VERSION ""

NS_ :

BS_:

BU_:

BO_ 227 TBI_Temp: 1 Vector__XXX
 SG_ TBI_Temp : 0|1@1- (1,0) [0|0] "" Vector__XXX

BO_ 211 TBI_MAP: 1 Vector__XXX
 SG_ TBI_MAP : 0|1@1- (1,0) [0|0] "" Vector__XXX

BO_ 195 TBI: 1 Vector__XXX
 SG_ TBI : 0|1@1- (1,0) [0|0] "" Vector__XXX

BO_ 179 Strain_Gauge: 1 Vector__XXX
 SG_ Strain_Gauge : 0|1@1- (1,0) [0|0] "" Vector__XXX

BO_ 163 TPMS: 1 Vector__XXX
 SG_ TPMS : 0|1@1- (1,0) [0|0] "" Vector__XXX

BO_ 242 Rear_Brake_Fluid_Pressure: 1 Vector__XXX
 SG_ Rear_Brake_Fluid_Pressure : 0|8@1+ (0.0392,0) [0|9.996] "Bar" Vector__XXX

BO_ 226 Front_Brake_Fluid_Pressure: 1 Vector__XXX
 SG_ Front_Brake_Fluid_Pressure : 0|8@1+ (0.0392,0) [0|9.996] "Bar" Vector__XXX

BO_ 210 Accel_Pedal_Pos: 1 Vector__XXX
 SG_ Accel_Pedal_Pos : 0|1@1- (1,0) [0|0] "" Vector__XXX

BO_ 194 Brake_Pedal_Pos: 1 Vector__XXX
 SG_ Brake_Pedal_Pos : 0|1@1- (1,0) [0|0] "" Vector__XXX

BO_ 178 Front_Brake_Disk_Temp: 4 Vector__XXX
 SG_ R_Front_Brake_Disk_Temp : 16|10@1- (0.12219,22.56128) [-40|85.00037] "degC" Vector__XXX
 SG_ L_Front_Brake_Disk_Temp : 0|10@1- (0.12219,22.56128) [-40|85.00037] "degC" Vector__XXX

BO_ 162 Rear_Brake_Disk_Temp: 4 Vector__XXX
 SG_ R_Rear_Brake_Disk_Temp : 16|10@1- (0.12219,22.56128) [-40|85.00037] "degC" Vector__XXX
 SG_ L_Rear_Brake_Disk_Temp : 0|10@1- (0.12219,22.56128) [-40|85.00037] "degC" Vector__XXX

BO_ 241 Balance_Bar: 1 Vector__XXX
 SG_ Balance_Bar : 0|1@1- (1,0) [0|0] "" Vector__XXX

BO_ 225 Fuel_Pressure: 1 Vector__XXX
 SG_ Fuel_Pressure : 0|8@1+ (0.0392,0) [0|9.996] "Bar" Vector__XXX

BO_ 209 Battery_Current: 1 Vector__XXX
 SG_ Battery_Current : 0|1@1- (1,0) [0|0] "A" Vector__XXX

BO_ 193 Battery_Voltage: 1 Vector__XXX
 SG_ Battery_Voltage : 0|1@1- (1,0) [0|0] "V" Vector__XXX

BO_ 514 Gear_Pos: 1 Vector__XXX
 SG_ Gear_Pos : 0|8@1+ (1,0) [0|6] "Gear" Vector__XXX

BO_ 177 GPS: 1 Vector__XXX
 SG_ GPS : 0|1@1- (1,0) [0|0] "" Vector__XXX

BO_ 769 Speed: 1 Vector__XXX
 SG_ Speed : 0|8@1+ (1,0) [0|255] "km/h" Vector__XXX

BO_ 257 Lambda_Sensor: 1 Vector__XXX
 SG_ Lambda_Sensor : 0|8@1+ (0.01,0) [0|2.55] "" Vector__XXX

BO_ 513 Air_Temp: 1 Vector__XXX
 SG_ Air_Temp : 0|8@1+ (1,0) [0|255] "degC" Vector__XXX

BO_ 258 MAP: 2 Vector__XXX
 SG_ MAP : 0|10@1+ (250,0) [0|255750] "Pa" Vector__XXX

BO_ 2 RPM: 2 Vector__XXX
 SG_ RPM_Sensor : 0|16@1+ (1,0) [0|13000] "RPM" Vector__XXX

BO_ 259 TPS: 1 Vector__XXX
 SG_ TPS : 0|8@1+ (1,0) [0|255] "%" Vector__XXX

BO_ 518 Water_Temp: 1 Vector__XXX
 SG_ Water_Temp : 0|8@1+ (1,0) [0|255] "degC" Vector__XXX

BO_ 1 Oil_Pressure: 1 Vector__XXX
 SG_ Oil_Pressure : 0|8@1+ (0.0392,0) [0|9.996] "Bar" Vector__XXX

BO_ 515 Oil_Temp: 1 Vector__XXX
 SG_ Oil_Temp : 0|8@1+ (1,0) [0|255] "degC" Vector__XXX

BO_ 161 Intercooler_Output_Pressure: 1 Vector__XXX
 SG_ Intercooler_Output_Pressure : 0|1@1- (1,0) [0|0] "" Vector__XXX

BO_ 15 Turbo_Intercooler_Pressure: 1 Vector__XXX
 SG_ Turbo_Intercooler_Pressure : 0|1@1- (1,0) [0|0] "" Vector__XXX

BO_ 14 Rest_Turbo_Pressure: 1 Vector__XXX
 SG_ Rest_Turbo_Pressure : 0|1@1- (1,0) [0|0] "" Vector__XXX

BO_ 13 Intercooler_Output_Temp: 1 Vector__XXX
 SG_ Intercooler_Output_Temp : 0|1@1- (1,0) [0|0] "degC" Vector__XXX

BO_ 12 Turbo_Intercooler_Temp: 1 Vector__XXX
 SG_ Turbo_Intercooler_Temp : 0|1@1- (1,0) [0|0] "degC" Vector__XXX

BO_ 11 Rest_Turbo_Temp: 1 Vector__XXX
 SG_ Rest_Turbo_Temp : 0|1@1- (1,0) [0|0] "degC" Vector__XXX

BO_ 1029 Rear_Susp_Pos: 4 Vector__XXX
 SG_ R_Rear_Susp_Pos : 16|10@1+ (0.088,0) [0|90.024] "deg" Vector__XXX
 SG_ L_Rear_Susp_Pos : 0|10@1+ (0.088,0) [0|90.024] "deg" Vector__XXX

BO_ 1028 Front_Susp_Pos: 4 Vector__XXX
 SG_ R_Front_Susp_Pos : 16|10@1+ (0.088,0) [0|90.024] "deg" Vector__XXX
 SG_ L_Front_Susp_Pos : 0|10@1+ (0.088,0) [0|90.024] "deg" Vector__XXX

BO_ 10 Steering_Wheel_Pos: 1 Vector__XXX
 SG_ Steering_Wheel_Pos : 0|1@1- (1,0) [0|0] "deg" Vector__XXX

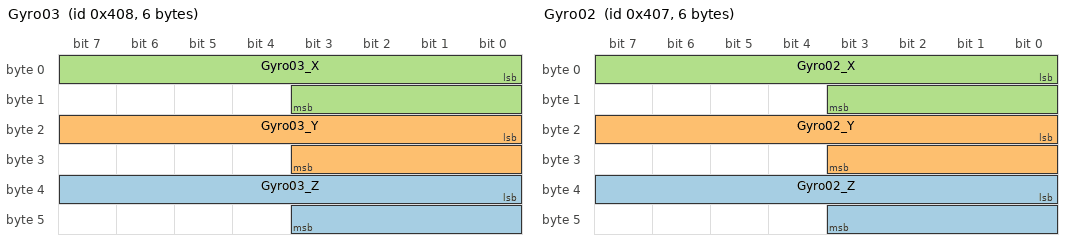
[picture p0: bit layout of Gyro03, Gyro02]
BO_ 1032 Gyro03: 6 Vector__XXX
 SG_ Gyro03_Z : 32|12@1- (0.125,0) [-256|255.875] "deg/s" Vector__XXX
 SG_ Gyro03_Y : 16|12@1- (0.125,0) [-256|255.875] "deg/s" Vector__XXX
 SG_ Gyro03_X : 0|12@1- (0.125,0) [-256|255.875] "deg/s" Vector__XXX

BO_ 1031 Gyro02: 6 Vector__XXX
 SG_ Gyro02_Z : 32|12@1- (0.125,0) [-256|255.875] "deg/s" Vector__XXX
 SG_ Gyro02_Y : 16|12@1- (0.125,0) [-256|255.875] "deg/s" Vector__XXX
 SG_ Gyro02_X : 0|12@1- (0.125,0) [-256|255.875] "deg/s" Vector__XXX

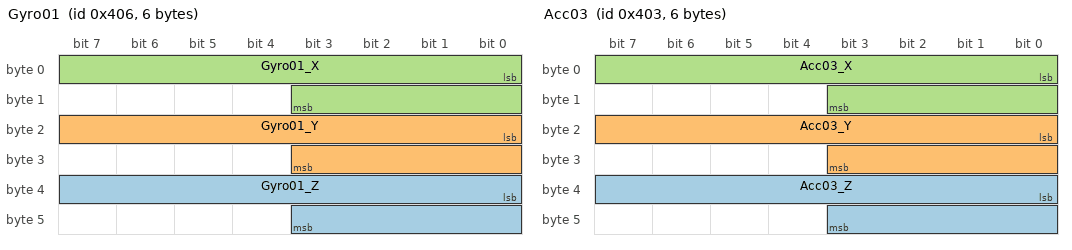
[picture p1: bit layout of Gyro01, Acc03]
BO_ 1030 Gyro01: 6 Vector__XXX
 SG_ Gyro01_Z : 32|12@1- (0.125,0) [-256|255.875] "deg/s" Vector__XXX
 SG_ Gyro01_Y : 16|12@1- (0.125,0) [-256|255.875] "deg/s" Vector__XXX
 SG_ Gyro01_X : 0|12@1- (0.125,0) [-256|255.875] "deg/s" Vector__XXX

BO_ 1027 Acc03: 6 Vector__XXX
 SG_ Acc03_Z : 32|12@1- (0.002,0) [-4.096|4.094] "G" Vector__XXX
 SG_ Acc03_Y : 16|12@1- (0.002,0) [-4.096|4.094] "G" Vector__XXX
 SG_ Acc03_X : 0|12@1- (0.002,0) [-4.096|4.094] "G" Vector__XXX

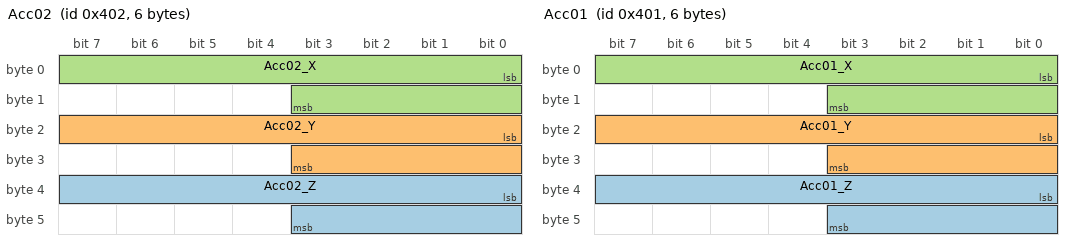
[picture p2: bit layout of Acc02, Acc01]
BO_ 1026 Acc02: 6 Vector__XXX
 SG_ Acc02_Z : 32|12@1- (0.002,0) [-4.096|4.094] "G" Vector__XXX
 SG_ Acc02_Y : 16|12@1- (0.002,0) [-4.096|4.094] "G" Vector__XXX
 SG_ Acc02_X : 0|12@1- (0.002,0) [-4.096|4.094] "G" Vector__XXX

BO_ 1025 Acc01: 6 Vector__XXX
 SG_ Acc01_Z : 32|12@1- (0.002,0) [-4.096|4.094] "G" Vector__XXX
 SG_ Acc01_Y : 16|12@1- (0.002,0) [-4.096|4.094] "G" Vector__XXX
 SG_ Acc01_X : 0|12@1- (0.002,0) [-4.096|4.094] "G" Vector__XXX

BA_DEF_  "BusType" STRING ;
BA_DEF_DEF_  "BusType" "CAN";
